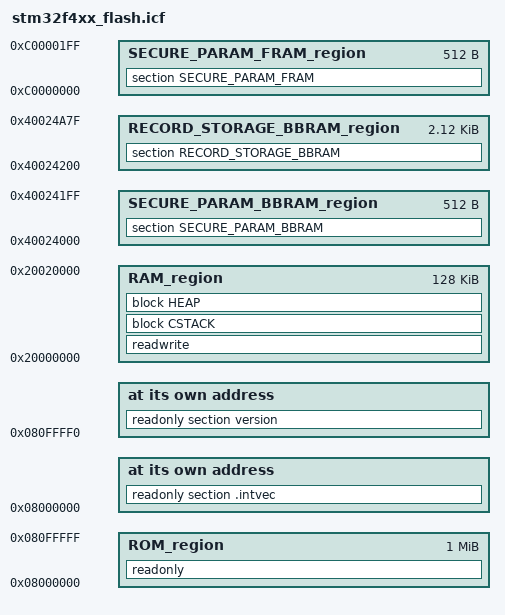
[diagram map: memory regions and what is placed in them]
/*###ICF### Section handled by ICF editor, don't touch! ****/
/*-Editor annotation file-*/
/* IcfEditorFile="$TOOLKIT_DIR$\config\ide\IcfEditor\cortex_v1_0.xml" */
/*-Specials-*/
define symbol __ICFEDIT_intvec_start__ = 0x08000000;
/*-Memory Regions-*/
define symbol __ICFEDIT_region_ROM_start__ = 0x08000000;
define symbol __ICFEDIT_region_ROM_end__   = 0x080FFFFF;
define symbol __ICFEDIT_region_RAM_start__ = 0x20000000;
define symbol __ICFEDIT_region_RAM_end__   = 0x20020000;
/*-Sizes-*/
define symbol __ICFEDIT_size_cstack__ = 0x400;
define symbol __ICFEDIT_size_heap__   = 0x200;
/**** End of ICF editor section. ###ICF###*/



/*** Symbols ***/
/*define symbol __region_NO_INIT_BBRAM_start__    = 0x40024000;*/   /* STM32 Battery Backed RAM */

define symbol __region_SECURE_PARAM_start__       = 0x40024000;        /* 512 bytes */
define symbol __region_SECURE_PARAM_end__         = 0x400241FF;

define symbol __region_RECORD_STORAGE_start__     = 0x40024200;      /* 2048 byte record array + 128 bytes for other vars */
define symbol __region_RECORD_STORAGE_end__       = 0x40024A7F;

/*define symbol __region_NO_INIT_BBRAM_end__      = 0x40024FFF;*/   /* STM32 Battery Backed RAM */

define symbol __region_SECURE_PARAM_FRAM_start__  = 0xC0000000;   /* FRAM Alais 512 bytes*/
define symbol __region_SECURE_PARAM_FRAM_end__    = 0xC00001FF;



/*** Regions ***/
define memory mem with size = 4G;
define region ROM_region            = mem:[from __ICFEDIT_region_ROM_start__  to __ICFEDIT_region_ROM_end__];
define region RAM_region            = mem:[from __ICFEDIT_region_RAM_start__  to __ICFEDIT_region_RAM_end__];

/*define region NO_INIT_BBRAM_region  = mem:[from __region_NO_INIT_BBRAM_start__ to __region_NO_INIT_BBRAM_end__];*/
define region SECURE_PARAM_BBRAM_region   = mem:[from __region_SECURE_PARAM_start__ to __region_SECURE_PARAM_end__];
define region RECORD_STORAGE_BBRAM_region = mem:[from __region_RECORD_STORAGE_start__ to __region_RECORD_STORAGE_end__];
define region SECURE_PARAM_FRAM_region    = mem:[from __region_SECURE_PARAM_FRAM_start__ to __region_SECURE_PARAM_FRAM_end__];

define block CSTACK    with alignment = 8, size = __ICFEDIT_size_cstack__   { };
define block HEAP      with alignment = 8, size = __ICFEDIT_size_heap__     { };

initialize by copy { readwrite };
do not initialize  { section .noinit };

place at address mem:__ICFEDIT_intvec_start__ { readonly section .intvec };

place in ROM_region   { readonly };
place in RAM_region   { readwrite,
                        block CSTACK, block HEAP };

place at address mem: 0x080FFFF0    { readonly section version };

/* do not initialize { rw section NO_INIT_BBRAM }; */
/* place in NO_INIT_BBRAM_region { section NO_INIT_BBRAM }; */

do not initialize { rw section SECURE_PARAM_BBRAM };
place in SECURE_PARAM_BBRAM_region { section SECURE_PARAM_BBRAM };

do not initialize { rw section RECORD_STORAGE_BBRAM };
place in RECORD_STORAGE_BBRAM_region { section RECORD_STORAGE_BBRAM };

do not initialize { rw section SECURE_PARAM_FRAM };
place in SECURE_PARAM_FRAM_region { section SECURE_PARAM_FRAM };

